AUTOSAR XML (schema 4-2-2)
package /STELLANTIS/EPT/SASWCs
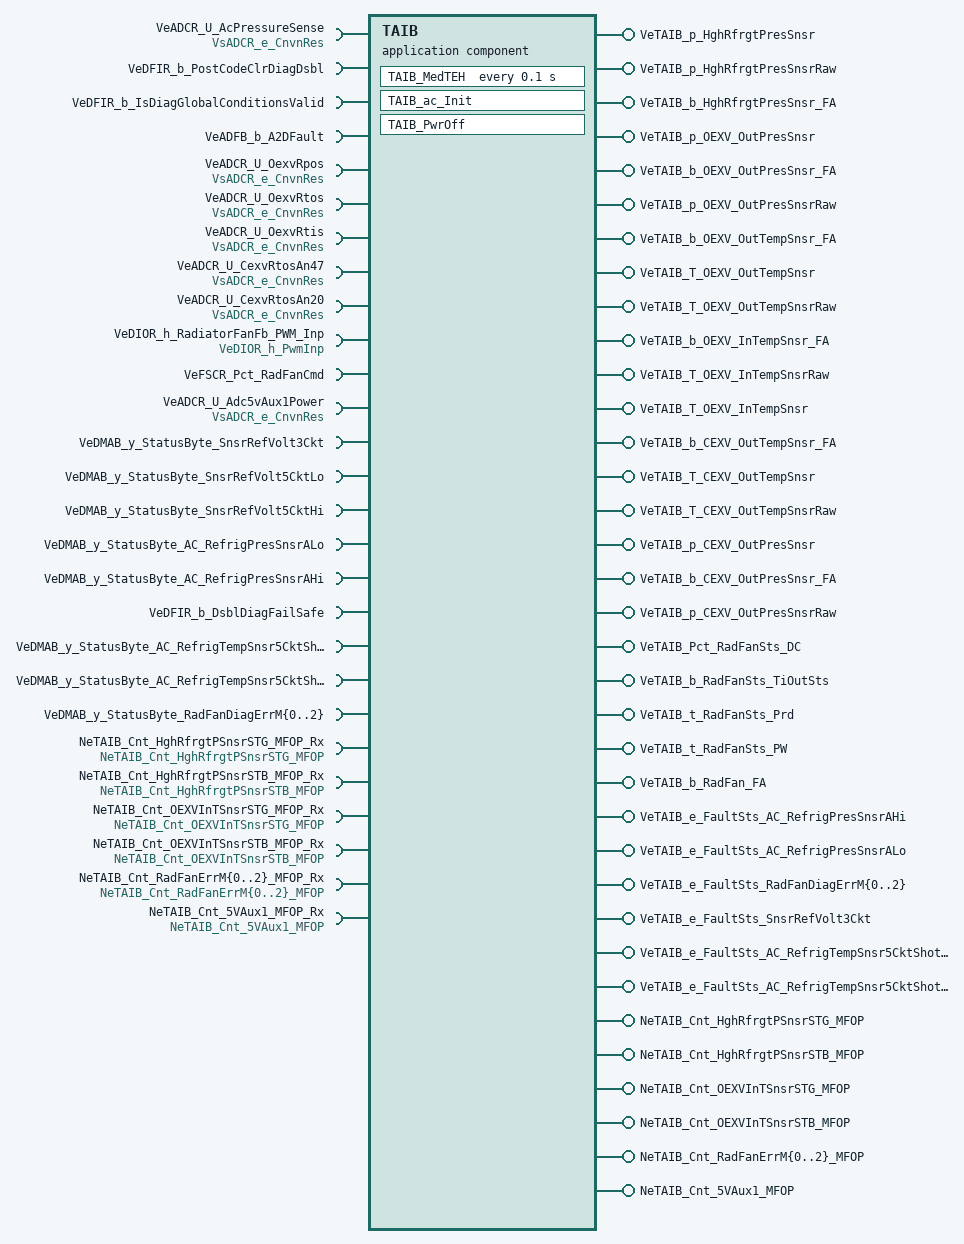
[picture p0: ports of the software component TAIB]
  application sw component type TAIB
    23 x require port:
      VeADCR_U_AcPressureSense: variation-point={short-label=vpVeADCR_U_AcPressureSense, sw-syscond=1}, nonqueued-receiver-com-spec{data-element=VsADCR_e_CnvnRes, init-value={short-label=DefaultInitValue_IDTRAdcInpResData, fields=[0, 0]}}, required-interface=VsADCR_e_CnvnRes
      VeDFIR_b_PostCodeClrDiagDsbl: variation-point={short-label=vpVeDFIR_b_PostCodeClrDiagDsbl, sw-syscond=1}, nonqueued-receiver-com-spec{data-element=Value, init-value=0}, required-interface=VeDFIR_b_PostCodeClrDiagDsbl
      VeDFIR_b_IsDiagGlobalConditionsValid: variation-point={short-label=vpVeDFIR_b_IsDiagGlobalConditionsValid, sw-syscond=1}, nonqueued-receiver-com-spec{data-element=Value, init-value=0}, required-interface=VeDFIR_b_IsDiagGlobalConditionsValid
      VeADFB_b_A2DFault: variation-point={short-label=vpVeADFB_b_A2DFault, sw-syscond=1}, nonqueued-receiver-com-spec{data-element=Value, init-value=0}, required-interface=VeADFB_b_A2DFault
      VeADCR_U_OexvRpos: variation-point={short-label=vpVeADCR_U_OexvRpos, sw-syscond=1}, nonqueued-receiver-com-spec{data-element=VsADCR_e_CnvnRes, init-value={short-label=DefaultInitValue_IDTRAdcInpResData, fields=[0, 0]}}, required-interface=VsADCR_e_CnvnRes
      VeADCR_U_OexvRtos: variation-point={short-label=vpVeADCR_U_OexvRtos, sw-syscond=1}, nonqueued-receiver-com-spec{data-element=VsADCR_e_CnvnRes, init-value={short-label=DefaultInitValue_IDTRAdcInpResData, fields=[0, 0]}}, required-interface=VsADCR_e_CnvnRes
      VeADCR_U_OexvRtis: variation-point={short-label=vpVeADCR_U_OexvRtis, sw-syscond=1}, nonqueued-receiver-com-spec{data-element=VsADCR_e_CnvnRes, init-value={short-label=DefaultInitValue_IDTRAdcInpResData, fields=[0, 0]}}, required-interface=VsADCR_e_CnvnRes
      VeADCR_U_CexvRtosAn47: variation-point={short-label=vpVeADCR_U_CexvRtosAn47, sw-syscond=1}, nonqueued-receiver-com-spec{data-element=VsADCR_e_CnvnRes, init-value={short-label=DefaultInitValue_IDTRAdcInpResData, fields=[0, 0]}}, required-interface=VsADCR_e_CnvnRes
      VeADCR_U_CexvRtosAn20: variation-point={short-label=vpVeADCR_U_CexvRtosAn20, sw-syscond=1}, nonqueued-receiver-com-spec{data-element=VsADCR_e_CnvnRes, init-value={short-label=DefaultInitValue_IDTRAdcInpResData, fields=[0, 0]}}, required-interface=VsADCR_e_CnvnRes
      VeDIOR_h_RadiatorFanFb_PWM_Inp: variation-point={short-label=vpVeDIOR_h_RadiatorFanFb_PWM_Inp, sw-syscond=1}, required-interface=VeDIOR_h_PwmInp
        required-com-specs:
          data-element=VeDIOR_Pct_PwmInp_DC, init-value=0
          data-element=VeDIOR_t_PwmInp_PW, init-value=0
          data-element=VeDIOR_t_PwmInp_Prd, init-value=0
          data-element=VeDIOR_b_PwmInp_TiOutSts, init-value=0
          data-element=VeDIOR_b_PwmInp_EnbldSts, init-value=0
          data-element=VeDIOR_b_IsPinHi, init-value=0
      VeFSCR_Pct_RadFanCmd: variation-point={short-label=vpVeFSCR_Pct_RadFanCmd, sw-syscond=1}, nonqueued-receiver-com-spec{data-element=Value, init-value=0}, required-interface=VeFSCR_Pct_RadFanCmd
      VeADCR_U_Adc5vAux1Power: variation-point={short-label=vpVeADCR_U_Adc5vAux1Power, sw-syscond=1}, nonqueued-receiver-com-spec{data-element=VsADCR_e_CnvnRes, init-value={short-label=DefaultInitValue_IDTRAdcInpResData, fields=[0, 0]}}, required-interface=VsADCR_e_CnvnRes
      VeDMAB_y_StatusByte_SnsrRefVolt3Ckt: variation-point={short-label=vpVeDMAB_y_StatusByte_SnsrRefVolt3Ckt, sw-syscond=1}, nonqueued-receiver-com-spec{data-element=Value, init-value=0}, required-interface=VeDMAB_y_StatusByte_SnsrRefVolt3Ckt
      VeDMAB_y_StatusByte_SnsrRefVolt5CktLo: variation-point={short-label=vpVeDMAB_y_StatusByte_SnsrRefVolt5CktLo, sw-syscond=1}, nonqueued-receiver-com-spec{data-element=Value, init-value=0}, required-interface=VeDMAB_y_StatusByte_SnsrRefVolt5CktLo
      VeDMAB_y_StatusByte_SnsrRefVolt5CktHi: variation-point={short-label=vpVeDMAB_y_StatusByte_SnsrRefVolt5CktHi, sw-syscond=1}, nonqueued-receiver-com-spec{data-element=Value, init-value=0}, required-interface=VeDMAB_y_StatusByte_SnsrRefVolt5CktHi
      VeDMAB_y_StatusByte_AC_RefrigPresSnsrALo: variation-point={short-label=vpVeDMAB_y_StatusByte_AC_RefrigPresSnsrALo, sw-syscond=1}, nonqueued-receiver-com-spec{data-element=Value, init-value=0}, required-interface=VeDMAB_y_StatusByte_AC_RefrigPresSnsrALo
      VeDMAB_y_StatusByte_AC_RefrigPresSnsrAHi: variation-point={short-label=vpVeDMAB_y_StatusByte_AC_RefrigPresSnsrAHi, sw-syscond=1}, nonqueued-receiver-com-spec{data-element=Value, init-value=0}, required-interface=VeDMAB_y_StatusByte_AC_RefrigPresSnsrAHi
      VeDFIR_b_DsblDiagFailSafe: variation-point={short-label=vpVeDFIR_b_DsblDiagFailSafe, sw-syscond=1}, nonqueued-receiver-com-spec{data-element=Value, init-value=0}, required-interface=VeDFIR_b_DsblDiagFailSafe
      VeDMAB_y_StatusByte_AC_RefrigTempSnsr5CktShotoGro: variation-point={short-label=vpVeDMAB_y_StatusByte_AC_RefrigTempSnsr5CktShotoGro, sw-syscond=1}, nonqueued-receiver-com-spec{data-element=Value, init-value=0}, required-interface=VeDMAB_y_StatusByte_AC_RefrigTempSnsr5CktShotoGro
      VeDMAB_y_StatusByte_AC_RefrigTempSnsr5CktShotoBat: variation-point={short-label=vpVeDMAB_y_StatusByte_AC_RefrigTempSnsr5CktShotoBat, sw-syscond=1}, nonqueued-receiver-com-spec{data-element=Value, init-value=0}, required-interface=VeDMAB_y_StatusByte_AC_RefrigTempSnsr5CktShotoBat
      VeDMAB_y_StatusByte_RadFanDiagErrM{0..2}: variation-point={short-label=vpVeDMAB_y_StatusByte_RadFanDiagErrM{0..2}, sw-syscond=1}, nonqueued-receiver-com-spec{data-element=Value, init-value=0}, required-interface=VeDMAB_y_StatusByte_RadFanDiagErrM{0..2}
    31 x provide port:
      VeTAIB_p_HghRfrgtPresSnsr: variation-point={short-label=vpVeTAIB_p_HghRfrgtPresSnsr, sw-syscond=1}, nonqueued-sender-com-spec{data-element=Value, init-value=0}, provided-interface=VeTAIB_p_HghRfrgtPresSnsr
      VeTAIB_p_HghRfrgtPresSnsrRaw: variation-point={short-label=vpVeTAIB_p_HghRfrgtPresSnsrRaw, sw-syscond=1}, nonqueued-sender-com-spec{data-element=Value, init-value=0}, provided-interface=VeTAIB_p_HghRfrgtPresSnsrRaw
      VeTAIB_b_HghRfrgtPresSnsr_FA: variation-point={short-label=vpVeTAIB_b_HghRfrgtPresSnsr_FA, sw-syscond=1}, nonqueued-sender-com-spec{data-element=Value, init-value=0}, provided-interface=VeTAIB_b_HghRfrgtPresSnsr_FA
      VeTAIB_p_OEXV_OutPresSnsr: variation-point={short-label=vpVeTAIB_p_OEXV_OutPresSnsr, sw-syscond=1}, nonqueued-sender-com-spec{data-element=Value, init-value=0}, provided-interface=VeTAIB_p_OEXV_OutPresSnsr
      VeTAIB_b_OEXV_OutPresSnsr_FA: variation-point={short-label=vpVeTAIB_b_OEXV_OutPresSnsr_FA, sw-syscond=1}, nonqueued-sender-com-spec{data-element=Value, init-value=0}, provided-interface=VeTAIB_b_OEXV_OutPresSnsr_FA
      VeTAIB_p_OEXV_OutPresSnsrRaw: variation-point={short-label=vpVeTAIB_p_OEXV_OutPresSnsrRaw, sw-syscond=1}, nonqueued-sender-com-spec{data-element=Value, init-value=0}, provided-interface=VeTAIB_p_OEXV_OutPresSnsrRaw
      VeTAIB_b_OEXV_OutTempSnsr_FA: variation-point={short-label=vpVeTAIB_b_OEXV_OutTempSnsr_FA, sw-syscond=1}, nonqueued-sender-com-spec{data-element=Value, init-value=0}, provided-interface=VeTAIB_b_OEXV_OutTempSnsr_FA
      VeTAIB_T_OEXV_OutTempSnsr: variation-point={short-label=vpVeTAIB_T_OEXV_OutTempSnsr, sw-syscond=1}, nonqueued-sender-com-spec{data-element=Value, init-value=0}, provided-interface=VeTAIB_T_OEXV_OutTempSnsr
      VeTAIB_T_OEXV_OutTempSnsrRaw: variation-point={short-label=vpVeTAIB_T_OEXV_OutTempSnsrRaw, sw-syscond=1}, nonqueued-sender-com-spec{data-element=Value, init-value=0}, provided-interface=VeTAIB_T_OEXV_OutTempSnsrRaw
      VeTAIB_b_OEXV_InTempSnsr_FA: variation-point={short-label=vpVeTAIB_b_OEXV_InTempSnsr_FA, sw-syscond=1}, nonqueued-sender-com-spec{data-element=Value, init-value=0}, provided-interface=VeTAIB_b_OEXV_InTempSnsr_FA
      VeTAIB_T_OEXV_InTempSnsrRaw: variation-point={short-label=vpVeTAIB_T_OEXV_InTempSnsrRaw, sw-syscond=1}, nonqueued-sender-com-spec{data-element=Value, init-value=0}, provided-interface=VeTAIB_T_OEXV_InTempSnsrRaw
      VeTAIB_T_OEXV_InTempSnsr: variation-point={short-label=vpVeTAIB_T_OEXV_InTempSnsr, sw-syscond=1}, nonqueued-sender-com-spec{data-element=Value, init-value=0}, provided-interface=VeTAIB_T_OEXV_InTempSnsr
      VeTAIB_b_CEXV_OutTempSnsr_FA: variation-point={short-label=vpVeTAIB_b_CEXV_OutTempSnsr_FA, sw-syscond=1}, nonqueued-sender-com-spec{data-element=Value, init-value=0}, provided-interface=VeTAIB_b_CEXV_OutTempSnsr_FA
      VeTAIB_T_CEXV_OutTempSnsr: variation-point={short-label=vpVeTAIB_T_CEXV_OutTempSnsr, sw-syscond=1}, nonqueued-sender-com-spec{data-element=Value, init-value=0}, provided-interface=VeTAIB_T_CEXV_OutTempSnsr
      VeTAIB_T_CEXV_OutTempSnsrRaw: variation-point={short-label=vpVeTAIB_T_CEXV_OutTempSnsrRaw, sw-syscond=1}, nonqueued-sender-com-spec{data-element=Value, init-value=0}, provided-interface=VeTAIB_T_CEXV_OutTempSnsrRaw
      VeTAIB_p_CEXV_OutPresSnsr: variation-point={short-label=vpVeTAIB_p_CEXV_OutPresSnsr, sw-syscond=1}, nonqueued-sender-com-spec{data-element=Value, init-value=0}, provided-interface=VeTAIB_p_CEXV_OutPresSnsr
      VeTAIB_b_CEXV_OutPresSnsr_FA: variation-point={short-label=vpVeTAIB_b_CEXV_OutPresSnsr_FA, sw-syscond=1}, nonqueued-sender-com-spec{data-element=Value, init-value=0}, provided-interface=VeTAIB_b_CEXV_OutPresSnsr_FA
      VeTAIB_p_CEXV_OutPresSnsrRaw: variation-point={short-label=vpVeTAIB_p_CEXV_OutPresSnsrRaw, sw-syscond=1}, nonqueued-sender-com-spec{data-element=Value, init-value=0}, provided-interface=VeTAIB_p_CEXV_OutPresSnsrRaw
      VeTAIB_Pct_RadFanSts_DC: variation-point={short-label=vpVeTAIB_Pct_RadFanSts_DC, sw-syscond=1}, nonqueued-sender-com-spec{data-element=Value, init-value=0}, provided-interface=VeTAIB_Pct_RadFanSts_DC
      VeTAIB_b_RadFanSts_TiOutSts: variation-point={short-label=vpVeTAIB_b_RadFanSts_TiOutSts, sw-syscond=1}, nonqueued-sender-com-spec{data-element=Value, init-value=0}, provided-interface=VeTAIB_b_RadFanSts_TiOutSts
      VeTAIB_t_RadFanSts_Prd: variation-point={short-label=vpVeTAIB_t_RadFanSts_Prd, sw-syscond=1}, nonqueued-sender-com-spec{data-element=Value, init-value=0}, provided-interface=VeTAIB_t_RadFanSts_Prd
      VeTAIB_t_RadFanSts_PW: variation-point={short-label=vpVeTAIB_t_RadFanSts_PW, sw-syscond=1}, nonqueued-sender-com-spec{data-element=Value, init-value=0}, provided-interface=VeTAIB_t_RadFanSts_PW
      VeTAIB_b_RadFan_FA: variation-point={short-label=vpVeTAIB_b_RadFan_FA, sw-syscond=1}, nonqueued-sender-com-spec{data-element=Value, init-value=0}, provided-interface=VeTAIB_b_RadFan_FA
      VeTAIB_e_FaultSts_AC_RefrigPresSnsrAHi: variation-point={short-label=vpVeTAIB_e_FaultSts_AC_RefrigPresSnsrAHi, sw-syscond=1}, nonqueued-sender-com-spec{data-element=Value, init-value=CeDFIB_e_Init}, provided-interface=VeTAIB_e_FaultSts_AC_RefrigPresSnsrAHi
      VeTAIB_e_FaultSts_AC_RefrigPresSnsrALo: variation-point={short-label=vpVeTAIB_e_FaultSts_AC_RefrigPresSnsrALo, sw-syscond=1}, nonqueued-sender-com-spec{data-element=Value, init-value=CeDFIB_e_Init}, provided-interface=VeTAIB_e_FaultSts_AC_RefrigPresSnsrALo
      VeTAIB_e_FaultSts_RadFanDiagErrM{0..2}: variation-point={short-label=vpVeTAIB_e_FaultSts_RadFanDiagErrM{0..2}, sw-syscond=1}, nonqueued-sender-com-spec{data-element=Value, init-value=CeDFIB_e_Init}, provided-interface=VeTAIB_e_FaultSts_RadFanDiagErrM{0..2}
      VeTAIB_e_FaultSts_SnsrRefVolt3Ckt: variation-point={short-label=vpVeTAIB_e_FaultSts_SnsrRefVolt3Ckt, sw-syscond=1}, nonqueued-sender-com-spec{data-element=Value, init-value=CeDFIB_e_Init}, provided-interface=VeTAIB_e_FaultSts_SnsrRefVolt3Ckt
      VeTAIB_e_FaultSts_AC_RefrigTempSnsr5CktShotoGro: variation-point={short-label=vpVeTAIB_e_FaultSts_AC_RefrigTempSnsr5CktShotoGro, sw-syscond=1}, nonqueued-sender-com-spec{data-element=Value, init-value=CeDFIB_e_Init}, provided-interface=VeTAIB_e_FaultSts_AC_RefrigTempSnsr5CktShotoGro
      VeTAIB_e_FaultSts_AC_RefrigTempSnsr5CktShotoBat: variation-point={short-label=vpVeTAIB_e_FaultSts_AC_RefrigTempSnsr5CktShotoBat, sw-syscond=1}, nonqueued-sender-com-spec{data-element=Value, init-value=CeDFIB_e_Init}, provided-interface=VeTAIB_e_FaultSts_AC_RefrigTempSnsr5CktShotoBat
    8 x require port:
      NeTAIB_Cnt_HghRfrgtPSnsrSTG_MFOP_Rx: variation-point={short-label=vpNeTAIB_Cnt_HghRfrgtPSnsrSTG_MFOP_Rx, sw-syscond=1}, nv-require-com-spec{init-value=0, variable=NeTAIB_Cnt_HghRfrgtPSnsrSTG_MFOP}, required-interface=NeTAIB_Cnt_HghRfrgtPSnsrSTG_MFOP
      NeTAIB_Cnt_HghRfrgtPSnsrSTB_MFOP_Rx: variation-point={short-label=vpNeTAIB_Cnt_HghRfrgtPSnsrSTB_MFOP_Rx, sw-syscond=1}, nv-require-com-spec{init-value=0, variable=NeTAIB_Cnt_HghRfrgtPSnsrSTB_MFOP}, required-interface=NeTAIB_Cnt_HghRfrgtPSnsrSTB_MFOP
      NeTAIB_Cnt_OEXVInTSnsrSTG_MFOP_Rx: variation-point={short-label=vpNeTAIB_Cnt_OEXVInTSnsrSTG_MFOP_Rx, sw-syscond=1}, nv-require-com-spec{init-value=0, variable=NeTAIB_Cnt_OEXVInTSnsrSTG_MFOP}, required-interface=NeTAIB_Cnt_OEXVInTSnsrSTG_MFOP
      NeTAIB_Cnt_OEXVInTSnsrSTB_MFOP_Rx: variation-point={short-label=vpNeTAIB_Cnt_OEXVInTSnsrSTB_MFOP_Rx, sw-syscond=1}, nv-require-com-spec{init-value=0, variable=NeTAIB_Cnt_OEXVInTSnsrSTB_MFOP}, required-interface=NeTAIB_Cnt_OEXVInTSnsrSTB_MFOP
      NeTAIB_Cnt_RadFanErrM{0..2}_MFOP_Rx: variation-point={short-label=vpNeTAIB_Cnt_RadFanErrM{0..2}_MFOP_Rx, sw-syscond=1}, nv-require-com-spec{init-value=0, variable=NeTAIB_Cnt_RadFanErrM{0..2}_MFOP}, required-interface=NeTAIB_Cnt_RadFanErrM{0..2}_MFOP
      NeTAIB_Cnt_5VAux1_MFOP_Rx: variation-point={short-label=vpNeTAIB_Cnt_5VAux1_MFOP_Rx, sw-syscond=1}, nv-require-com-spec{init-value=0, variable=NeTAIB_Cnt_5VAux1_MFOP}, required-interface=NeTAIB_Cnt_5VAux1_MFOP
    8 x provide port:
      NeTAIB_Cnt_HghRfrgtPSnsrSTG_MFOP: nv-provide-com-spec{ram-block-init-value=0, variable=NeTAIB_Cnt_HghRfrgtPSnsrSTG_MFOP}, provided-interface=NeTAIB_Cnt_HghRfrgtPSnsrSTG_MFOP
      NeTAIB_Cnt_HghRfrgtPSnsrSTB_MFOP: nv-provide-com-spec{ram-block-init-value=0, variable=NeTAIB_Cnt_HghRfrgtPSnsrSTB_MFOP}, provided-interface=NeTAIB_Cnt_HghRfrgtPSnsrSTB_MFOP
      NeTAIB_Cnt_OEXVInTSnsrSTG_MFOP: nv-provide-com-spec{ram-block-init-value=0, variable=NeTAIB_Cnt_OEXVInTSnsrSTG_MFOP}, provided-interface=NeTAIB_Cnt_OEXVInTSnsrSTG_MFOP
      NeTAIB_Cnt_OEXVInTSnsrSTB_MFOP: nv-provide-com-spec{ram-block-init-value=0, variable=NeTAIB_Cnt_OEXVInTSnsrSTB_MFOP}, provided-interface=NeTAIB_Cnt_OEXVInTSnsrSTB_MFOP
      NeTAIB_Cnt_RadFanErrM{0..2}_MFOP: nv-provide-com-spec{ram-block-init-value=0, variable=NeTAIB_Cnt_RadFanErrM{0..2}_MFOP}, provided-interface=NeTAIB_Cnt_RadFanErrM{0..2}_MFOP
      NeTAIB_Cnt_5VAux1_MFOP: nv-provide-com-spec{ram-block-init-value=0, variable=NeTAIB_Cnt_5VAux1_MFOP}, provided-interface=NeTAIB_Cnt_5VAux1_MFOP
    behavior IB_TAIB: data-type-mapping=[msADTtoIDTMapping, ADTtoIDTMapping], handle-termination-and-restart=NO-SUPPORT, included-data-type-set=data-type=[TeTAIB_e_FltDtctnSt, TeTAIB_e_ToutMeasSt]
      timing event Event_MedTEH: start-on-event=TAIB_MedTEH, period=0.1
      init event Event_TAIB_ac_Init: start-on-event=TAIB_ac_Init
      init event Event_PwrOff: start-on-event=TAIB_PwrOff
      runnable TAIB_ac_Init
        data-receive-point-by-arguments:
          8 x access:
            IN_NeTAIB_Cnt_5VAux1_MFOP_Rx_NeTAIB_Cnt_5VAux1_MFOP: accessed-variable=NeTAIB_Cnt_5VAux1_MFOP_Rx.NeTAIB_Cnt_5VAux1_MFOP, variation-point={short-label=vpIN_NeTAIB_Cnt_5VAux1_MFOP_Rx_NeTAIB_Cnt_5VAux1_MFOP, sw-syscond=1}
            IN_NeTAIB_Cnt_HghRfrgtPSnsrSTB_MFOP_Rx_NeTAIB_Cnt_HghRfrgtPSnsrSTB_MFOP: accessed-variable=NeTAIB_Cnt_HghRfrgtPSnsrSTB_MFOP_Rx.NeTAIB_Cnt_HghRfrgtPSnsrSTB_MFOP, variation-point={short-label=vpIN_NeTAIB_Cnt_HghRfrgtPSnsrSTB_MFOP_Rx_NeTAIB_Cnt_HghRfrgtPSnsrSTB_MFOP, sw-syscond=1}
            IN_NeTAIB_Cnt_HghRfrgtPSnsrSTG_MFOP_Rx_NeTAIB_Cnt_HghRfrgtPSnsrSTG_MFOP: accessed-variable=NeTAIB_Cnt_HghRfrgtPSnsrSTG_MFOP_Rx.NeTAIB_Cnt_HghRfrgtPSnsrSTG_MFOP, variation-point={short-label=vpIN_NeTAIB_Cnt_HghRfrgtPSnsrSTG_MFOP_Rx_NeTAIB_Cnt_HghRfrgtPSnsrSTG_MFOP, sw-syscond=1}
            IN_NeTAIB_Cnt_OEXVInTSnsrSTB_MFOP_Rx_NeTAIB_Cnt_OEXVInTSnsrSTB_MFOP: accessed-variable=NeTAIB_Cnt_OEXVInTSnsrSTB_MFOP_Rx.NeTAIB_Cnt_OEXVInTSnsrSTB_MFOP, variation-point={short-label=vpIN_NeTAIB_Cnt_OEXVInTSnsrSTB_MFOP_Rx_NeTAIB_Cnt_OEXVInTSnsrSTB_MFOP, sw-syscond=1}
            IN_NeTAIB_Cnt_OEXVInTSnsrSTG_MFOP_Rx_NeTAIB_Cnt_OEXVInTSnsrSTG_MFOP: accessed-variable=NeTAIB_Cnt_OEXVInTSnsrSTG_MFOP_Rx.NeTAIB_Cnt_OEXVInTSnsrSTG_MFOP, variation-point={short-label=vpIN_NeTAIB_Cnt_OEXVInTSnsrSTG_MFOP_Rx_NeTAIB_Cnt_OEXVInTSnsrSTG_MFOP, sw-syscond=1}
            IN_NeTAIB_Cnt_RadFanErrM{0..2}_MFOP_Rx_NeTAIB_Cnt_RadFanErrM{0..2}_MFOP: accessed-variable=NeTAIB_Cnt_RadFanErrM{0..2}_MFOP_Rx.NeTAIB_Cnt_RadFanErrM{0..2}_MFOP, variation-point={short-label=vpIN_NeTAIB_Cnt_RadFanErrM{0..2}_MFOP_Rx_NeTAIB_Cnt_RadFanErrM{0..2}_MFOP, sw-syscond=1}
        data-send-points:
          23 x access:
            OUT_VeTAIB_p_HghRfrgtPresSnsrRaw_Value: accessed-variable=VeTAIB_p_HghRfrgtPresSnsrRaw.Value, variation-point={short-label=vpOUT_VeTAIB_p_HghRfrgtPresSnsrRaw_Value, sw-syscond=1}
            OUT_VeTAIB_p_HghRfrgtPresSnsr_Value: accessed-variable=VeTAIB_p_HghRfrgtPresSnsr.Value, variation-point={short-label=vpOUT_VeTAIB_p_HghRfrgtPresSnsr_Value, sw-syscond=1}
            OUT_VeTAIB_e_FaultSts_AC_RefrigPresSnsrAHi_Value: accessed-variable=VeTAIB_e_FaultSts_AC_RefrigPresSnsrAHi.Value, variation-point={short-label=vpOUT_VeTAIB_e_FaultSts_AC_RefrigPresSnsrAHi_Value, sw-syscond=1}
            OUT_VeTAIB_e_FaultSts_AC_RefrigPresSnsrALo_Value: accessed-variable=VeTAIB_e_FaultSts_AC_RefrigPresSnsrALo.Value, variation-point={short-label=vpOUT_VeTAIB_e_FaultSts_AC_RefrigPresSnsrALo_Value, sw-syscond=1}
            OUT_VeTAIB_p_OEXV_OutPresSnsrRaw_Value: accessed-variable=VeTAIB_p_OEXV_OutPresSnsrRaw.Value, variation-point={short-label=vpOUT_VeTAIB_p_OEXV_OutPresSnsrRaw_Value, sw-syscond=1}
            OUT_VeTAIB_p_OEXV_OutPresSnsr_Value: accessed-variable=VeTAIB_p_OEXV_OutPresSnsr.Value, variation-point={short-label=vpOUT_VeTAIB_p_OEXV_OutPresSnsr_Value, sw-syscond=1}
            OUT_VeTAIB_p_CEXV_OutPresSnsrRaw_Value: accessed-variable=VeTAIB_p_CEXV_OutPresSnsrRaw.Value, variation-point={short-label=vpOUT_VeTAIB_p_CEXV_OutPresSnsrRaw_Value, sw-syscond=1}
            OUT_VeTAIB_p_CEXV_OutPresSnsr_Value: accessed-variable=VeTAIB_p_CEXV_OutPresSnsr.Value, variation-point={short-label=vpOUT_VeTAIB_p_CEXV_OutPresSnsr_Value, sw-syscond=1}
            OUT_VeTAIB_T_OEXV_OutTempSnsrRaw_Value: accessed-variable=VeTAIB_T_OEXV_OutTempSnsrRaw.Value, variation-point={short-label=vpOUT_VeTAIB_T_OEXV_OutTempSnsrRaw_Value, sw-syscond=1}
            OUT_VeTAIB_T_OEXV_OutTempSnsr_Value: accessed-variable=VeTAIB_T_OEXV_OutTempSnsr.Value, variation-point={short-label=vpOUT_VeTAIB_T_OEXV_OutTempSnsr_Value, sw-syscond=1}
            OUT_VeTAIB_T_CEXV_OutTempSnsrRaw_Value: accessed-variable=VeTAIB_T_CEXV_OutTempSnsrRaw.Value, variation-point={short-label=vpOUT_VeTAIB_T_CEXV_OutTempSnsrRaw_Value, sw-syscond=1}
            OUT_VeTAIB_T_CEXV_OutTempSnsr_Value: accessed-variable=VeTAIB_T_CEXV_OutTempSnsr.Value, variation-point={short-label=vpOUT_VeTAIB_T_CEXV_OutTempSnsr_Value, sw-syscond=1}
            OUT_VeTAIB_Pct_RadFanSts_DC_Value: accessed-variable=VeTAIB_Pct_RadFanSts_DC.Value, variation-point={short-label=vpOUT_VeTAIB_Pct_RadFanSts_DC_Value, sw-syscond=1}
            OUT_VeTAIB_t_RadFanSts_Prd_Value: accessed-variable=VeTAIB_t_RadFanSts_Prd.Value, variation-point={short-label=vpOUT_VeTAIB_t_RadFanSts_Prd_Value, sw-syscond=1}
            OUT_VeTAIB_t_RadFanSts_PW_Value: accessed-variable=VeTAIB_t_RadFanSts_PW.Value, variation-point={short-label=vpOUT_VeTAIB_t_RadFanSts_PW_Value, sw-syscond=1}
            OUT_VeTAIB_e_FaultSts_RadFanDiagErrM{0..2}_Value: accessed-variable=VeTAIB_e_FaultSts_RadFanDiagErrM{0..2}.Value, variation-point={short-label=vpOUT_VeTAIB_e_FaultSts_RadFanDiagErrM{0..2}_Value, sw-syscond=1}
            OUT_VeTAIB_e_FaultSts_SnsrRefVolt3Ckt_Value: accessed-variable=VeTAIB_e_FaultSts_SnsrRefVolt3Ckt.Value, variation-point={short-label=vpOUT_VeTAIB_e_FaultSts_SnsrRefVolt3Ckt_Value, sw-syscond=1}
            OUT_VeTAIB_T_OEXV_InTempSnsrRaw_Value: accessed-variable=VeTAIB_T_OEXV_InTempSnsrRaw.Value, variation-point={short-label=vpOUT_VeTAIB_T_OEXV_InTempSnsrRaw_Value, sw-syscond=1}
            OUT_VeTAIB_T_OEXV_InTempSnsr_Value: accessed-variable=VeTAIB_T_OEXV_InTempSnsr.Value, variation-point={short-label=vpOUT_VeTAIB_T_OEXV_InTempSnsr_Value, sw-syscond=1}
            OUT_VeTAIB_e_FaultSts_AC_RefrigTempSnsr5CktShotoGro_Value: accessed-variable=VeTAIB_e_FaultSts_AC_RefrigTempSnsr5CktShotoGro.Value, variation-point={short-label=vpOUT_VeTAIB_e_FaultSts_AC_RefrigTempSnsr5CktShotoGro_Value, sw-syscond=1}
            OUT_VeTAIB_e_FaultSts_AC_RefrigTempSnsr5CktShotoBat_Value: accessed-variable=VeTAIB_e_FaultSts_AC_RefrigTempSnsr5CktShotoBat.Value, variation-point={short-label=vpOUT_VeTAIB_e_FaultSts_AC_RefrigTempSnsr5CktShotoBat_Value, sw-syscond=1}
      runnable TAIB_MedTEH
        data-receive-point-by-arguments:
          24 x access:
            IN_VeADCR_U_AcPressureSense_VsADCR_e_CnvnRes: accessed-variable=VeADCR_U_AcPressureSense.VsADCR_e_CnvnRes, variation-point={short-label=vpIN_VeADCR_U_AcPressureSense_VsADCR_e_CnvnRes, sw-syscond=1}
            IN_VeADCR_U_Adc5vAux1Power_VsADCR_e_CnvnRes: accessed-variable=VeADCR_U_Adc5vAux1Power.VsADCR_e_CnvnRes, variation-point={short-label=vpIN_VeADCR_U_Adc5vAux1Power_VsADCR_e_CnvnRes, sw-syscond=1}
            IN_VeADCR_U_CexvRtosAn20_VsADCR_e_CnvnRes: accessed-variable=VeADCR_U_CexvRtosAn20.VsADCR_e_CnvnRes, variation-point={short-label=vpIN_VeADCR_U_CexvRtosAn20_VsADCR_e_CnvnRes, sw-syscond=1}
            IN_VeADCR_U_CexvRtosAn47_VsADCR_e_CnvnRes: accessed-variable=VeADCR_U_CexvRtosAn47.VsADCR_e_CnvnRes, variation-point={short-label=vpIN_VeADCR_U_CexvRtosAn47_VsADCR_e_CnvnRes, sw-syscond=1}
            IN_VeADCR_U_OexvRpos_VsADCR_e_CnvnRes: accessed-variable=VeADCR_U_OexvRpos.VsADCR_e_CnvnRes, variation-point={short-label=vpIN_VeADCR_U_OexvRpos_VsADCR_e_CnvnRes, sw-syscond=1}
            IN_VeADCR_U_OexvRtis_VsADCR_e_CnvnRes: accessed-variable=VeADCR_U_OexvRtis.VsADCR_e_CnvnRes, variation-point={short-label=vpIN_VeADCR_U_OexvRtis_VsADCR_e_CnvnRes, sw-syscond=1}
            IN_VeADCR_U_OexvRtos_VsADCR_e_CnvnRes: accessed-variable=VeADCR_U_OexvRtos.VsADCR_e_CnvnRes, variation-point={short-label=vpIN_VeADCR_U_OexvRtos_VsADCR_e_CnvnRes, sw-syscond=1}
            IN_VeADFB_b_A2DFault_Value: accessed-variable=VeADFB_b_A2DFault.Value, variation-point={short-label=vpIN_VeADFB_b_A2DFault_Value, sw-syscond=1}
            IN_VeDFIR_b_DsblDiagFailSafe_Value: accessed-variable=VeDFIR_b_DsblDiagFailSafe.Value, variation-point={short-label=vpIN_VeDFIR_b_DsblDiagFailSafe_Value, sw-syscond=1}
            IN_VeDFIR_b_IsDiagGlobalConditionsValid_Value: accessed-variable=VeDFIR_b_IsDiagGlobalConditionsValid.Value, variation-point={short-label=vpIN_VeDFIR_b_IsDiagGlobalConditionsValid_Value, sw-syscond=1}
            IN_VeDFIR_b_PostCodeClrDiagDsbl_Value: accessed-variable=VeDFIR_b_PostCodeClrDiagDsbl.Value, variation-point={short-label=vpIN_VeDFIR_b_PostCodeClrDiagDsbl_Value, sw-syscond=1}
            IN_VeDIOR_h_RadiatorFanFb_PWM_Inp_VeDIOR_Pct_PwmInp_DC: accessed-variable=VeDIOR_h_RadiatorFanFb_PWM_Inp.VeDIOR_Pct_PwmInp_DC, variation-point={short-label=vpIN_VeDIOR_h_RadiatorFanFb_PWM_Inp_VeDIOR_Pct_PwmInp_DC, sw-syscond=1}
            IN_VeDIOR_h_RadiatorFanFb_PWM_Inp_VeDIOR_b_PwmInp_TiOutSts: accessed-variable=VeDIOR_h_RadiatorFanFb_PWM_Inp.VeDIOR_b_PwmInp_TiOutSts, variation-point={short-label=vpIN_VeDIOR_h_RadiatorFanFb_PWM_Inp_VeDIOR_b_PwmInp_TiOutSts, sw-syscond=1}
            IN_VeDIOR_h_RadiatorFanFb_PWM_Inp_VeDIOR_t_PwmInp_PW: accessed-variable=VeDIOR_h_RadiatorFanFb_PWM_Inp.VeDIOR_t_PwmInp_PW, variation-point={short-label=vpIN_VeDIOR_h_RadiatorFanFb_PWM_Inp_VeDIOR_t_PwmInp_PW, sw-syscond=1}
            IN_VeDIOR_h_RadiatorFanFb_PWM_Inp_VeDIOR_t_PwmInp_Prd: accessed-variable=VeDIOR_h_RadiatorFanFb_PWM_Inp.VeDIOR_t_PwmInp_Prd, variation-point={short-label=vpIN_VeDIOR_h_RadiatorFanFb_PWM_Inp_VeDIOR_t_PwmInp_Prd, sw-syscond=1}
            IN_VeDMAB_y_StatusByte_AC_RefrigPresSnsrAHi_Value: accessed-variable=VeDMAB_y_StatusByte_AC_RefrigPresSnsrAHi.Value, variation-point={short-label=vpIN_VeDMAB_y_StatusByte_AC_RefrigPresSnsrAHi_Value, sw-syscond=1}
            IN_VeDMAB_y_StatusByte_AC_RefrigPresSnsrALo_Value: accessed-variable=VeDMAB_y_StatusByte_AC_RefrigPresSnsrALo.Value, variation-point={short-label=vpIN_VeDMAB_y_StatusByte_AC_RefrigPresSnsrALo_Value, sw-syscond=1}
            IN_VeDMAB_y_StatusByte_AC_RefrigTempSnsr5CktShotoBat_Value: accessed-variable=VeDMAB_y_StatusByte_AC_RefrigTempSnsr5CktShotoBat.Value, variation-point={short-label=vpIN_VeDMAB_y_StatusByte_AC_RefrigTempSnsr5CktShotoBat_Value, sw-syscond=1}
            IN_VeDMAB_y_StatusByte_AC_RefrigTempSnsr5CktShotoGro_Value: accessed-variable=VeDMAB_y_StatusByte_AC_RefrigTempSnsr5CktShotoGro.Value, variation-point={short-label=vpIN_VeDMAB_y_StatusByte_AC_RefrigTempSnsr5CktShotoGro_Value, sw-syscond=1}
            IN_VeDMAB_y_StatusByte_RadFanDiagErrM{0..2}_Value: accessed-variable=VeDMAB_y_StatusByte_RadFanDiagErrM{0..2}.Value, variation-point={short-label=vpIN_VeDMAB_y_StatusByte_RadFanDiagErrM{0..2}_Value, sw-syscond=1}
            IN_VeDMAB_y_StatusByte_SnsrRefVolt3Ckt_Value: accessed-variable=VeDMAB_y_StatusByte_SnsrRefVolt3Ckt.Value, variation-point={short-label=vpIN_VeDMAB_y_StatusByte_SnsrRefVolt3Ckt_Value, sw-syscond=1}
            IN_VeFSCR_Pct_RadFanCmd_Value: accessed-variable=VeFSCR_Pct_RadFanCmd.Value, variation-point={short-label=vpIN_VeFSCR_Pct_RadFanCmd_Value, sw-syscond=1}
        data-send-points:
          31 x access:
            OUT_VeTAIB_p_HghRfrgtPresSnsr_Value: accessed-variable=VeTAIB_p_HghRfrgtPresSnsr.Value, variation-point={short-label=vpOUT_VeTAIB_p_HghRfrgtPresSnsr_Value, sw-syscond=1}
            OUT_VeTAIB_p_HghRfrgtPresSnsrRaw_Value: accessed-variable=VeTAIB_p_HghRfrgtPresSnsrRaw.Value, variation-point={short-label=vpOUT_VeTAIB_p_HghRfrgtPresSnsrRaw_Value, sw-syscond=1}
            OUT_VeTAIB_b_HghRfrgtPresSnsr_FA_Value: accessed-variable=VeTAIB_b_HghRfrgtPresSnsr_FA.Value, variation-point={short-label=vpOUT_VeTAIB_b_HghRfrgtPresSnsr_FA_Value, sw-syscond=1}
            OUT_VeTAIB_p_OEXV_OutPresSnsr_Value: accessed-variable=VeTAIB_p_OEXV_OutPresSnsr.Value, variation-point={short-label=vpOUT_VeTAIB_p_OEXV_OutPresSnsr_Value, sw-syscond=1}
            OUT_VeTAIB_p_OEXV_OutPresSnsrRaw_Value: accessed-variable=VeTAIB_p_OEXV_OutPresSnsrRaw.Value, variation-point={short-label=vpOUT_VeTAIB_p_OEXV_OutPresSnsrRaw_Value, sw-syscond=1}
            OUT_VeTAIB_b_OEXV_OutPresSnsr_FA_Value: accessed-variable=VeTAIB_b_OEXV_OutPresSnsr_FA.Value, variation-point={short-label=vpOUT_VeTAIB_b_OEXV_OutPresSnsr_FA_Value, sw-syscond=1}
            OUT_VeTAIB_b_OEXV_OutTempSnsr_FA_Value: accessed-variable=VeTAIB_b_OEXV_OutTempSnsr_FA.Value, variation-point={short-label=vpOUT_VeTAIB_b_OEXV_OutTempSnsr_FA_Value, sw-syscond=1}
            OUT_VeTAIB_T_OEXV_OutTempSnsrRaw_Value: accessed-variable=VeTAIB_T_OEXV_OutTempSnsrRaw.Value, variation-point={short-label=vpOUT_VeTAIB_T_OEXV_OutTempSnsrRaw_Value, sw-syscond=1}
            OUT_VeTAIB_T_OEXV_OutTempSnsr_Value: accessed-variable=VeTAIB_T_OEXV_OutTempSnsr.Value, variation-point={short-label=vpOUT_VeTAIB_T_OEXV_OutTempSnsr_Value, sw-syscond=1}
            OUT_VeTAIB_b_CEXV_OutTempSnsr_FA_Value: accessed-variable=VeTAIB_b_CEXV_OutTempSnsr_FA.Value, variation-point={short-label=vpOUT_VeTAIB_b_CEXV_OutTempSnsr_FA_Value, sw-syscond=1}
            OUT_VeTAIB_T_CEXV_OutTempSnsrRaw_Value: accessed-variable=VeTAIB_T_CEXV_OutTempSnsrRaw.Value, variation-point={short-label=vpOUT_VeTAIB_T_CEXV_OutTempSnsrRaw_Value, sw-syscond=1}
            OUT_VeTAIB_T_CEXV_OutTempSnsr_Value: accessed-variable=VeTAIB_T_CEXV_OutTempSnsr.Value, variation-point={short-label=vpOUT_VeTAIB_T_CEXV_OutTempSnsr_Value, sw-syscond=1}
            OUT_VeTAIB_p_CEXV_OutPresSnsr_Value: accessed-variable=VeTAIB_p_CEXV_OutPresSnsr.Value, variation-point={short-label=vpOUT_VeTAIB_p_CEXV_OutPresSnsr_Value, sw-syscond=1}
            OUT_VeTAIB_p_CEXV_OutPresSnsrRaw_Value: accessed-variable=VeTAIB_p_CEXV_OutPresSnsrRaw.Value, variation-point={short-label=vpOUT_VeTAIB_p_CEXV_OutPresSnsrRaw_Value, sw-syscond=1}
            OUT_VeTAIB_b_CEXV_OutPresSnsr_FA_Value: accessed-variable=VeTAIB_b_CEXV_OutPresSnsr_FA.Value, variation-point={short-label=vpOUT_VeTAIB_b_CEXV_OutPresSnsr_FA_Value, sw-syscond=1}
            OUT_VeTAIB_Pct_RadFanSts_DC_Value: accessed-variable=VeTAIB_Pct_RadFanSts_DC.Value, variation-point={short-label=vpOUT_VeTAIB_Pct_RadFanSts_DC_Value, sw-syscond=1}
            OUT_VeTAIB_b_RadFanSts_TiOutSts_Value: accessed-variable=VeTAIB_b_RadFanSts_TiOutSts.Value, variation-point={short-label=vpOUT_VeTAIB_b_RadFanSts_TiOutSts_Value, sw-syscond=1}
            OUT_VeTAIB_t_RadFanSts_Prd_Value: accessed-variable=VeTAIB_t_RadFanSts_Prd.Value, variation-point={short-label=vpOUT_VeTAIB_t_RadFanSts_Prd_Value, sw-syscond=1}
            OUT_VeTAIB_t_RadFanSts_PW_Value: accessed-variable=VeTAIB_t_RadFanSts_PW.Value, variation-point={short-label=vpOUT_VeTAIB_t_RadFanSts_PW_Value, sw-syscond=1}
            OUT_VeTAIB_b_RadFan_FA_Value: accessed-variable=VeTAIB_b_RadFan_FA.Value, variation-point={short-label=vpOUT_VeTAIB_b_RadFan_FA_Value, sw-syscond=1}
            OUT_VeTAIB_e_FaultSts_AC_RefrigPresSnsrALo_Value: accessed-variable=VeTAIB_e_FaultSts_AC_RefrigPresSnsrALo.Value, variation-point={short-label=vpOUT_VeTAIB_e_FaultSts_AC_RefrigPresSnsrALo_Value, sw-syscond=1}
            OUT_VeTAIB_e_FaultSts_SnsrRefVolt3Ckt_Value: accessed-variable=VeTAIB_e_FaultSts_SnsrRefVolt3Ckt.Value, variation-point={short-label=vpOUT_VeTAIB_e_FaultSts_SnsrRefVolt3Ckt_Value, sw-syscond=1}
            OUT_VeTAIB_e_FaultSts_RadFanDiagErrM0_Value: accessed-variable=VeTAIB_e_FaultSts_RadFanDiagErrM0.Value, variation-point={short-label=vpOUT_VeTAIB_e_FaultSts_RadFanDiagErrM0_Value, sw-syscond=1}
            OUT_VeTAIB_e_FaultSts_AC_RefrigPresSnsrAHi_Value: accessed-variable=VeTAIB_e_FaultSts_AC_RefrigPresSnsrAHi.Value, variation-point={short-label=vpOUT_VeTAIB_e_FaultSts_AC_RefrigPresSnsrAHi_Value, sw-syscond=1}
            OUT_VeTAIB_e_FaultSts_RadFanDiagErrM1_Value: accessed-variable=VeTAIB_e_FaultSts_RadFanDiagErrM1.Value, variation-point={short-label=vpOUT_VeTAIB_e_FaultSts_RadFanDiagErrM1_Value, sw-syscond=1}
            OUT_VeTAIB_e_FaultSts_RadFanDiagErrM2_Value: accessed-variable=VeTAIB_e_FaultSts_RadFanDiagErrM2.Value, variation-point={short-label=vpOUT_VeTAIB_e_FaultSts_RadFanDiagErrM2_Value, sw-syscond=1}
            OUT_VeTAIB_T_OEXV_InTempSnsr_Value: accessed-variable=VeTAIB_T_OEXV_InTempSnsr.Value, variation-point={short-label=vpOUT_VeTAIB_T_OEXV_InTempSnsr_Value, sw-syscond=1}
            OUT_VeTAIB_T_OEXV_InTempSnsrRaw_Value: accessed-variable=VeTAIB_T_OEXV_InTempSnsrRaw.Value, variation-point={short-label=vpOUT_VeTAIB_T_OEXV_InTempSnsrRaw_Value, sw-syscond=1}
            OUT_VeTAIB_b_OEXV_InTempSnsr_FA_Value: accessed-variable=VeTAIB_b_OEXV_InTempSnsr_FA.Value, variation-point={short-label=vpOUT_VeTAIB_b_OEXV_InTempSnsr_FA_Value, sw-syscond=1}
            OUT_VeTAIB_e_FaultSts_AC_RefrigTempSnsr5CktShotoBat_Value: accessed-variable=VeTAIB_e_FaultSts_AC_RefrigTempSnsr5CktShotoBat.Value, variation-point={short-label=vpOUT_VeTAIB_e_FaultSts_AC_RefrigTempSnsr5CktShotoBat_Value, sw-syscond=1}
            OUT_VeTAIB_e_FaultSts_AC_RefrigTempSnsr5CktShotoGro_Value: accessed-variable=VeTAIB_e_FaultSts_AC_RefrigTempSnsr5CktShotoGro.Value, variation-point={short-label=vpOUT_VeTAIB_e_FaultSts_AC_RefrigTempSnsr5CktShotoGro_Value, sw-syscond=1}
      runnable TAIB_PwrOff
        data-send-points:
          8 x access:
            OUT_NeTAIB_Cnt_HghRfrgtPSnsrSTG_MFOP_NeTAIB_Cnt_HghRfrgtPSnsrSTG_MFOP: accessed-variable=NeTAIB_Cnt_HghRfrgtPSnsrSTG_MFOP.NeTAIB_Cnt_HghRfrgtPSnsrSTG_MFOP
            OUT_NeTAIB_Cnt_HghRfrgtPSnsrSTB_MFOP_NeTAIB_Cnt_HghRfrgtPSnsrSTB_MFOP: accessed-variable=NeTAIB_Cnt_HghRfrgtPSnsrSTB_MFOP.NeTAIB_Cnt_HghRfrgtPSnsrSTB_MFOP
            OUT_NeTAIB_Cnt_OEXVInTSnsrSTG_MFOP_NeTAIB_Cnt_OEXVInTSnsrSTG_MFOP: accessed-variable=NeTAIB_Cnt_OEXVInTSnsrSTG_MFOP.NeTAIB_Cnt_OEXVInTSnsrSTG_MFOP
            OUT_NeTAIB_Cnt_OEXVInTSnsrSTB_MFOP_NeTAIB_Cnt_OEXVInTSnsrSTB_MFOP: accessed-variable=NeTAIB_Cnt_OEXVInTSnsrSTB_MFOP.NeTAIB_Cnt_OEXVInTSnsrSTB_MFOP
            OUT_NeTAIB_Cnt_RadFanErrM{0..2}_MFOP_NeTAIB_Cnt_RadFanErrM{0..2}_MFOP: accessed-variable=NeTAIB_Cnt_RadFanErrM{0..2}_MFOP.NeTAIB_Cnt_RadFanErrM{0..2}_MFOP
            OUT_NeTAIB_Cnt_5VAux1_MFOP_NeTAIB_Cnt_5VAux1_MFOP: accessed-variable=NeTAIB_Cnt_5VAux1_MFOP.NeTAIB_Cnt_5VAux1_MFOP
      8 x variation point proxy, all with category=CONDITION, condition-access=1:
        Variant_TAIB_5VAUX_Presence
        Variant_TAIB_CEXVOP_Presence
        Variant_TAIB_CEXVOT_Presence
        Variant_TAIB_HRPS_Presence
        Variant_TAIB_OEXVIT_Presence
        Variant_TAIB_OEXVOP_Presence
        Variant_TAIB_OEXVOT_Presence
        Variant_TAIB_RADFANFB_Presence
